VERSION ""

NS_ :

BS_:

BU_:

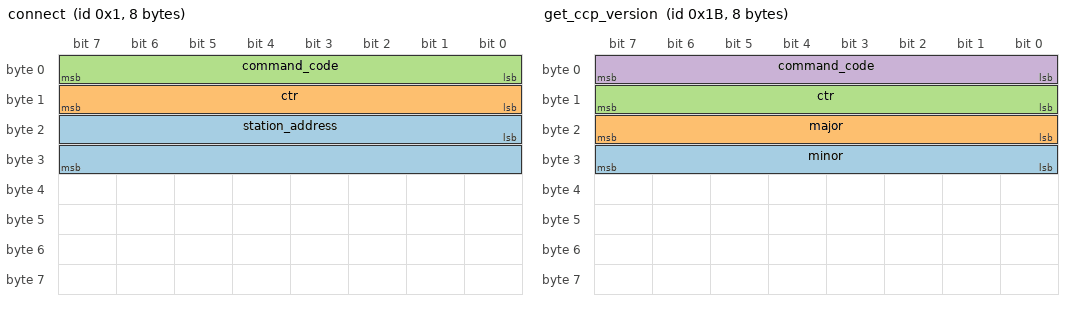
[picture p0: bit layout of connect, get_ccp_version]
BO_ 1 connect: 8 Vector__XXX
 SG_ station_address : 16|16@1+ (1,0) [0|0] "" Vector__XXX
 SG_ ctr : 15|8@0+ (1,0) [0|0] "" Vector__XXX
 SG_ command_code : 7|8@0+ (1,0) [0|0] "" Vector__XXX

BO_ 27 get_ccp_version: 8 Vector__XXX
 SG_ minor : 31|8@0+ (1,0) [0|0] "" Vector__XXX
 SG_ major : 23|8@0+ (1,0) [0|0] "" Vector__XXX
 SG_ ctr : 15|8@0+ (1,0) [0|0] "" Vector__XXX
 SG_ command_code : 7|8@0+ (1,0) [0|0] "" Vector__XXX

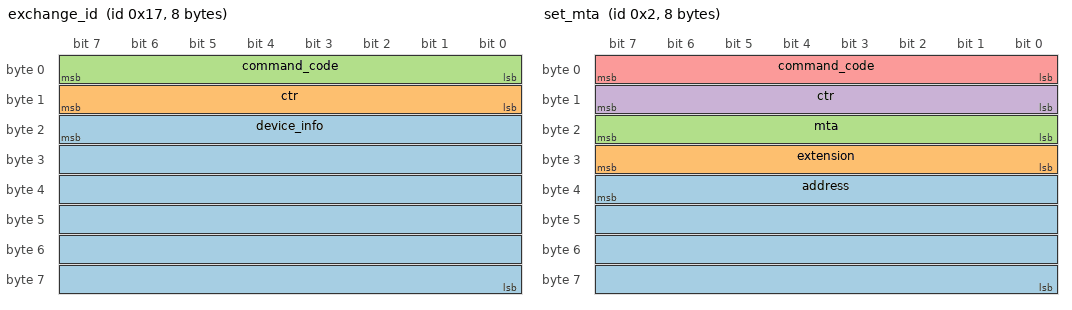
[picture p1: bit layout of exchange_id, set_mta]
BO_ 23 exchange_id: 8 Vector__XXX
 SG_ device_info : 23|48@0+ (1,0) [0|0] "" Vector__XXX
 SG_ ctr : 15|8@0+ (1,0) [0|0] "" Vector__XXX
 SG_ command_code : 7|8@0+ (1,0) [0|0] "" Vector__XXX

BO_ 2 set_mta: 8 Vector__XXX
 SG_ address : 39|32@0+ (1,0) [0|0] "" Vector__XXX
 SG_ extension : 31|8@0+ (1,0) [0|0] "" Vector__XXX
 SG_ mta : 23|8@0+ (1,0) [0|0] "" Vector__XXX
 SG_ ctr : 15|8@0+ (1,0) [0|0] "" Vector__XXX
 SG_ command_code : 7|8@0+ (1,0) [0|0] "" Vector__XXX

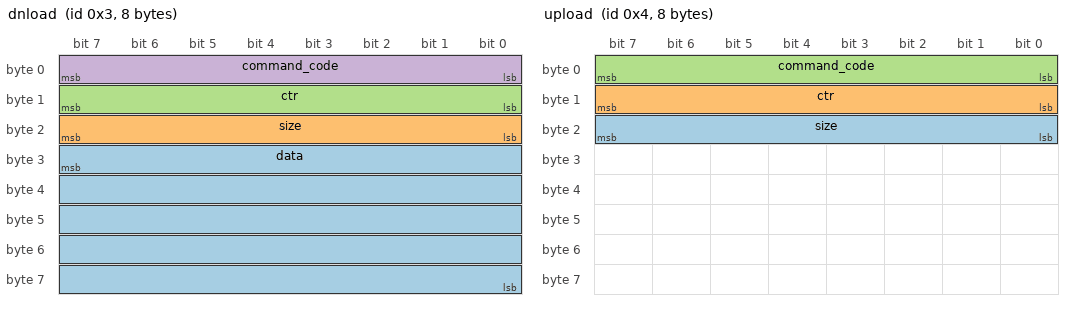
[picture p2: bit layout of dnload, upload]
BO_ 3 dnload: 8 Vector__XXX
 SG_ data : 31|40@0+ (1,0) [0|0] "" Vector__XXX
 SG_ size : 23|8@0+ (1,0) [0|0] "" Vector__XXX
 SG_ ctr : 15|8@0+ (1,0) [0|0] "" Vector__XXX
 SG_ command_code : 7|8@0+ (1,0) [0|0] "" Vector__XXX

BO_ 4 upload: 8 Vector__XXX
 SG_ size : 23|8@0+ (1,0) [0|0] "" Vector__XXX
 SG_ ctr : 15|8@0+ (1,0) [0|0] "" Vector__XXX
 SG_ command_code : 7|8@0+ (1,0) [0|0] "" Vector__XXX

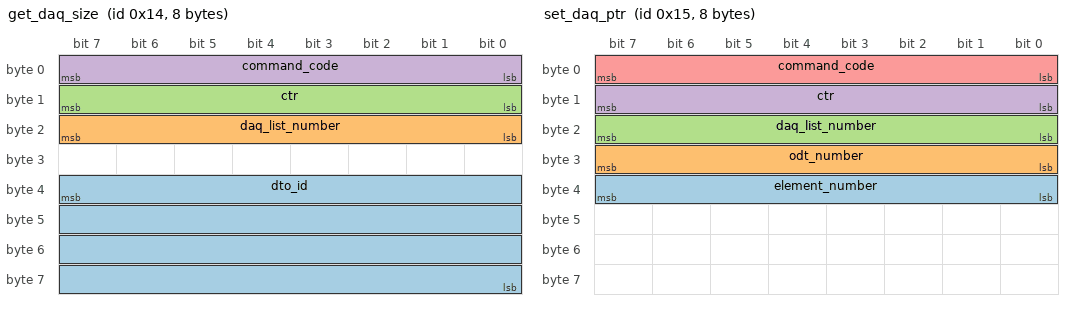
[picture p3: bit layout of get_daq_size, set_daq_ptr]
BO_ 20 get_daq_size: 8 Vector__XXX
 SG_ dto_id : 39|32@0+ (1,0) [0|0] "" Vector__XXX
 SG_ daq_list_number : 23|8@0+ (1,0) [0|0] "" Vector__XXX
 SG_ ctr : 15|8@0+ (1,0) [0|0] "" Vector__XXX
 SG_ command_code : 7|8@0+ (1,0) [0|0] "" Vector__XXX

BO_ 21 set_daq_ptr: 8 Vector__XXX
 SG_ element_number : 39|8@0+ (1,0) [0|0] "" Vector__XXX
 SG_ odt_number : 31|8@0+ (1,0) [0|0] "" Vector__XXX
 SG_ daq_list_number : 23|8@0+ (1,0) [0|0] "" Vector__XXX
 SG_ ctr : 15|8@0+ (1,0) [0|0] "" Vector__XXX
 SG_ command_code : 7|8@0+ (1,0) [0|0] "" Vector__XXX

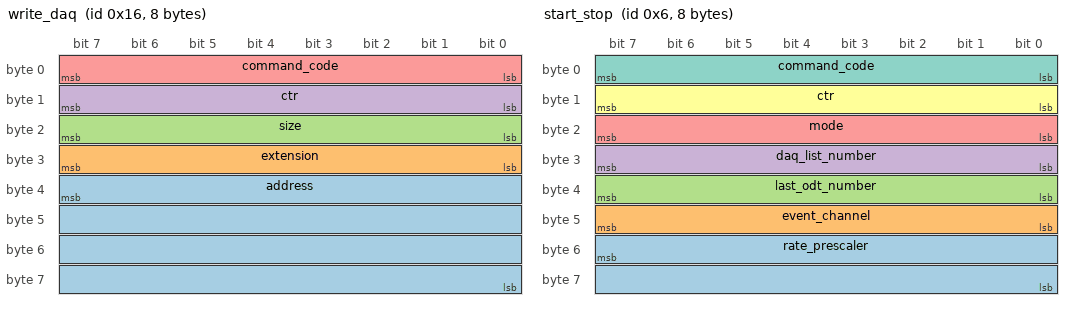
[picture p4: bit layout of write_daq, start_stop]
BO_ 22 write_daq: 8 Vector__XXX
 SG_ address : 39|32@0+ (1,0) [0|0] "" Vector__XXX
 SG_ extension : 31|8@0+ (1,0) [0|0] "" Vector__XXX
 SG_ size : 23|8@0+ (1,0) [0|0] "" Vector__XXX
 SG_ ctr : 15|8@0+ (1,0) [0|0] "" Vector__XXX
 SG_ command_code : 7|8@0+ (1,0) [0|0] "" Vector__XXX

BO_ 6 start_stop: 8 Vector__XXX
 SG_ rate_prescaler : 55|16@0+ (1,0) [0|0] "" Vector__XXX
 SG_ event_channel : 47|8@0+ (1,0) [0|0] "" Vector__XXX
 SG_ last_odt_number : 39|8@0+ (1,0) [0|0] "" Vector__XXX
 SG_ daq_list_number : 31|8@0+ (1,0) [0|0] "" Vector__XXX
 SG_ mode : 23|8@0+ (1,0) [0|0] "" Vector__XXX
 SG_ ctr : 15|8@0+ (1,0) [0|0] "" Vector__XXX
 SG_ command_code : 7|8@0+ (1,0) [0|0] "" Vector__XXX

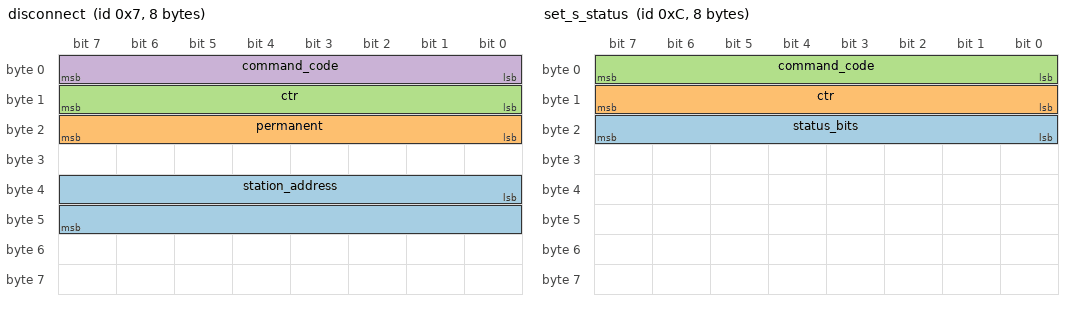
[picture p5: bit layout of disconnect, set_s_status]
BO_ 7 disconnect: 8 Vector__XXX
 SG_ station_address : 32|16@1+ (1,0) [0|0] "" Vector__XXX
 SG_ permanent : 23|8@0+ (1,0) [0|0] "" Vector__XXX
 SG_ ctr : 15|8@0+ (1,0) [0|0] "" Vector__XXX
 SG_ command_code : 7|8@0+ (1,0) [0|0] "" Vector__XXX

BO_ 12 set_s_status: 8 Vector__XXX
 SG_ status_bits : 23|8@0+ (1,0) [0|0] "" Vector__XXX
 SG_ ctr : 15|8@0+ (1,0) [0|0] "" Vector__XXX
 SG_ command_code : 7|8@0+ (1,0) [0|0] "" Vector__XXX

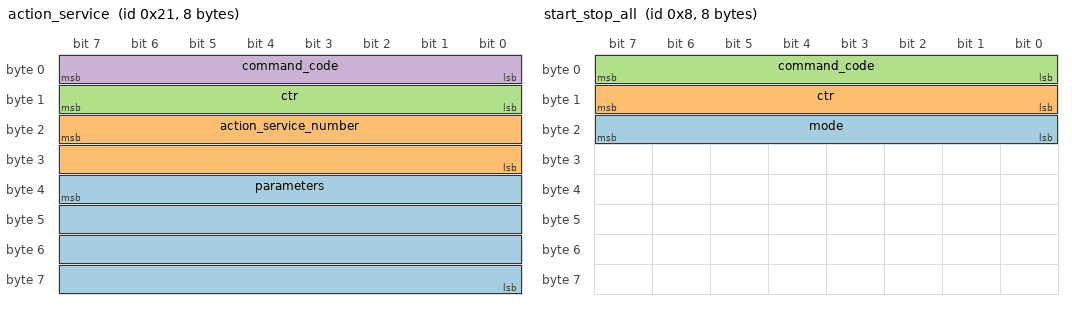
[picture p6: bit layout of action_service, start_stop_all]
BO_ 33 action_service: 8 Vector__XXX
 SG_ parameters : 39|32@0+ (1,0) [0|0] "" Vector__XXX
 SG_ action_service_number : 23|16@0+ (1,0) [0|0] "" Vector__XXX
 SG_ ctr : 15|8@0+ (1,0) [0|0] "" Vector__XXX
 SG_ command_code : 7|8@0+ (1,0) [0|0] "" Vector__XXX

BO_ 13 get_s_status: 8 Vector__XXX
 SG_ ctr : 15|8@0+ (1,0) [0|0] "" Vector__XXX
 SG_ command_code : 7|8@0+ (1,0) [0|0] "" Vector__XXX

BO_ 8 start_stop_all: 8 Vector__XXX
 SG_ mode : 23|8@0+ (1,0) [0|0] "" Vector__XXX
 SG_ ctr : 15|8@0+ (1,0) [0|0] "" Vector__XXX
 SG_ command_code : 7|8@0+ (1,0) [0|0] "" Vector__XXX
